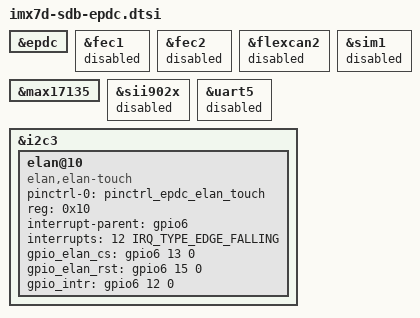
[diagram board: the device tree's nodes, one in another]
/*
 * Copyright (C) 2015 Freescale Semiconductor, Inc.
 *
 * This program is free software; you can redistribute it and/or modify
 * it under the terms of the GNU General Public License version 2 as
 * published by the Free Software Foundation.
 */

&epdc {
        status = "okay";
};

&fec1 {
	status = "disabled";
};

&fec2 {
	status = "disabled";
};

&flexcan2 {
	status = "disabled";
};

&max17135 {
        status = "okay";
};

&sii902x {
	status = "disabled";
};

&sim1 {
	status = "disabled";
};

&uart5 {
	status = "disabled";
};

&i2c3 {
	elan@10 {
		pinctrl-names = "default";
		pinctrl-0 = <&pinctrl_epdc_elan_touch>;
		compatible = "elan,elan-touch";
		reg = <0x10>;
		interrupt-parent = <&gpio6>;
		interrupts = <12 IRQ_TYPE_EDGE_FALLING>;
		gpio_elan_cs = <&gpio6 13 0>;
		gpio_elan_rst = <&gpio6 15 0>;
		gpio_intr = <&gpio6 12 0>;
		status = "okay";
	};
};
